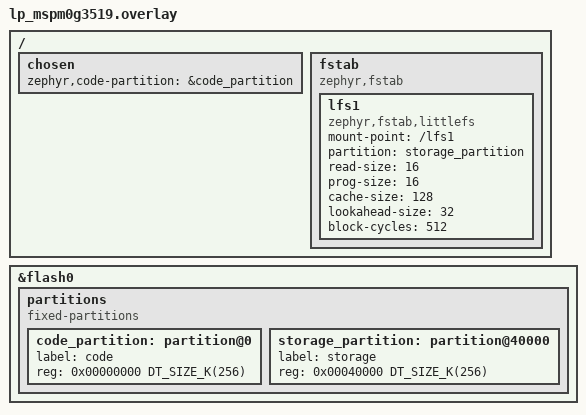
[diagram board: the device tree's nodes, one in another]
/*
 * Copyright (c) 2026 Texas Instruments Inc.
 *
 * SPDX-License-Identifier: Apache-2.0
 */

/ {
	chosen {
		zephyr,code-partition = &code_partition;
	};

	fstab {
		compatible = "zephyr,fstab";
		lfs1: lfs1 {
			compatible = "zephyr,fstab,littlefs";
			mount-point = "/lfs1";
			partition = <&storage_partition>;
			read-size = <16>;
			prog-size = <16>;
			cache-size = <128>;
			lookahead-size = <32>;
			block-cycles = <512>;
		};
	};
};

&flash0 {
	partitions {
		compatible = "fixed-partitions";
		#address-cells = <1>;
		#size-cells = <1>;

		code_partition: partition@0 {
			label = "code";
			reg = <0x00000000 DT_SIZE_K(256)>;
		};

		storage_partition: partition@40000 {
			label = "storage";
			reg = <0x00040000 DT_SIZE_K(256)>;
		};
	};
};

